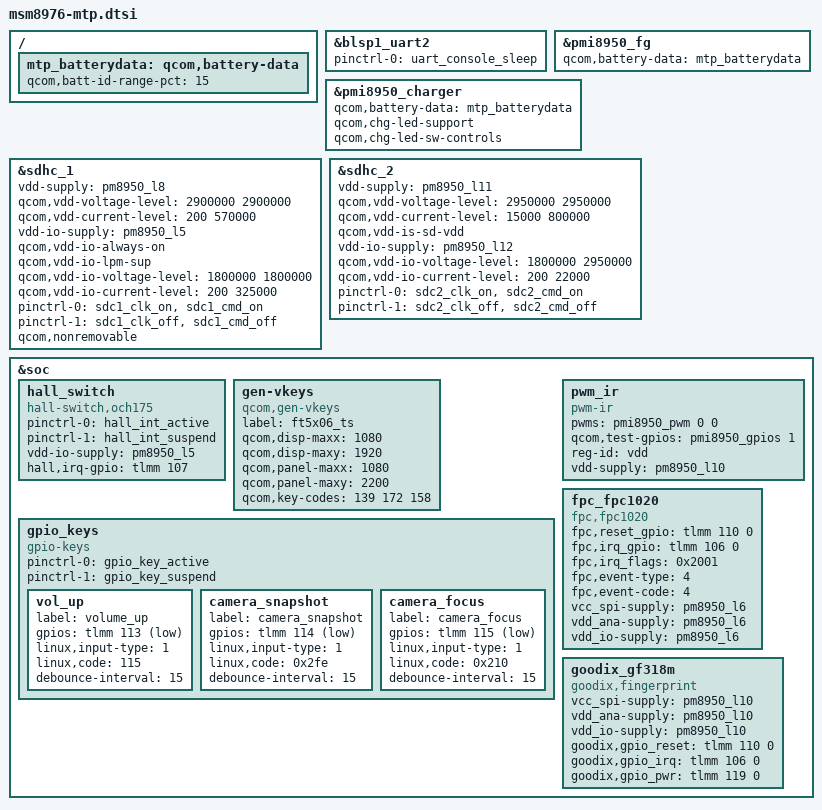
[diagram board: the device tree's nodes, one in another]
// SPDX-License-Identifier: GPL-2.0
// Copyright (c) 2015, The Linux Foundation. All rights reserved.
// Copyright (c) 2023-2024, Benarji Anand <benarji385@gmail.com>

#include "msm8976-camera-sensor-mtp.dtsi"
#include "msm8976-mdss-mtp.dtsi"

&blsp1_uart2 {
	status = "ok";
	pinctrl-names = "default";
	pinctrl-0 = <&uart_console_sleep>;
};

/ {
mtp_batterydata: qcom,battery-data {
	qcom,batt-id-range-pct = <15>;
	#include "batterydata-coslight-4000mah-4400mv.dtsi"
	#include "batterydata-coslight-4000mah-4400mv-10k.dtsi"
	#include "batterydata-sunwoda-4000mah-4400mv.dtsi"
	};
};

&pmi8950_fg {
	qcom,battery-data = <&mtp_batterydata>;
};

&pmi8950_charger {
	qcom,battery-data = <&mtp_batterydata>;
	qcom,chg-led-support;
	qcom,chg-led-sw-controls;
};

&sdhc_1 {
	vdd-supply = <&pm8950_l8>;
	qcom,vdd-voltage-level = <2900000 2900000>;
	qcom,vdd-current-level = <200 570000>;

	vdd-io-supply = <&pm8950_l5>;
	qcom,vdd-io-always-on;
	qcom,vdd-io-lpm-sup;
	qcom,vdd-io-voltage-level = <1800000 1800000>;
	qcom,vdd-io-current-level = <200 325000>;

	pinctrl-names = "active", "sleep";
	pinctrl-0 = <&sdc1_clk_on &sdc1_cmd_on>;
	pinctrl-1 = <&sdc1_clk_off &sdc1_cmd_off>;

	qcom,nonremovable;

	status = "ok";
};

&sdhc_2 {
	vdd-supply = <&pm8950_l11>;
	qcom,vdd-voltage-level = <2950000 2950000>;
	qcom,vdd-current-level = <15000 800000>;
	qcom,vdd-is-sd-vdd;

	vdd-io-supply = <&pm8950_l12>;
	qcom,vdd-io-voltage-level = <1800000 2950000>;
	qcom,vdd-io-current-level = <200 22000>;

	pinctrl-names = "active", "sleep";
	pinctrl-0 = <&sdc2_clk_on &sdc2_cmd_on>;
	pinctrl-1 = <&sdc2_clk_off &sdc2_cmd_off>;

	status = "ok";
};

&soc {
	hall_switch {
		compatible = "hall-switch,och175";
		pinctrl-names = "hall_active","hall_suspend";
		pinctrl-0 = <&hall_int_active>;
		pinctrl-1 = <&hall_int_suspend>;
		vdd-io-supply= <&pm8950_l5>;
		interrupt-names = "hall_irq";
		hall,irq-gpio = <&tlmm 107 0x00>;
	};

	gen-vkeys {
		compatible = "qcom,gen-vkeys";
		label = "ft5x06_ts";
		qcom,disp-maxx = <1080>;
		qcom,disp-maxy = <1920>;
		qcom,panel-maxx = <1080>;
		qcom,panel-maxy = <2200>;
		qcom,key-codes = <139 172 158>;
	};

	gpio_keys {
		compatible = "gpio-keys";
		pinctrl-names = "tlmm_gpio_key_active","tlmm_gpio_key_suspend";
		pinctrl-0 = <&gpio_key_active>;
		pinctrl-1 = <&gpio_key_suspend>;

		vol_up {
			label = "volume_up";
			gpios = <&tlmm 113 0x1>;
			linux,input-type = <1>;
			linux,code = <115>;
			debounce-interval = <15>;
		};

		camera_snapshot {
			label = "camera_snapshot";
			gpios = <&tlmm 114 0x1>;
			linux,input-type = <1>;
			linux,code = <0x2fe>;
			debounce-interval = <15>;
		};

		camera_focus {
			label = "camera_focus";
			gpios = <&tlmm 115 0x1>;
			linux,input-type = <1>;
			linux,code = <0x210>;
			debounce-interval = <15>;
		};
	};

	pwm_ir {
		compatible = "pwm-ir";
		pwms = <&pmi8950_pwm 0 0>;
		qcom,test-gpios = <&pmi8950_gpios 1 0>;
		reg-id = "vdd";
		vdd-supply = <&pm8950_l10>;
	};

	fpc_fpc1020 {
		compatible = "fpc,fpc1020";
		fpc,reset_gpio = <&tlmm 110 0>;
		fpc,irq_gpio = <&tlmm 106 0>;
		fpc,irq_flags = <0x2001>;
		fpc,event-type = <4>;
		fpc,event-code = <4>;
		vcc_spi-supply = <&pm8950_l6>;
		vdd_ana-supply = <&pm8950_l6>;
		vdd_io-supply = <&pm8950_l6>;
	};

	goodix_gf318m {
		compatible = "goodix,fingerprint";

		vcc_spi-supply  = <&pm8950_l10>;
		vdd_ana-supply  = <&pm8950_l10>;
		vdd_io-supply   = <&pm8950_l10>;

		goodix,gpio_reset =<&tlmm 110 0>;
		goodix,gpio_irq = <&tlmm 106 0>;
		goodix,gpio_pwr = <&tlmm 119 0>;

	};
};
